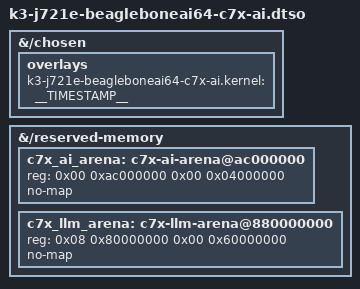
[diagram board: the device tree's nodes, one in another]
// SPDX-License-Identifier: MIT
// BeagleBone AI-64 C7x AI runtime overlay: reserves contiguous DDR tensor
// arenas (no-map) shared between Linux A72 and C7x DSP:
//   - 0xac000000  (64 MiB)  : primary / microbenchmark arena
//   - 0x880000000 (1.5 GiB) : large LLM model + KV cache + prefill arena (high DDR bank)

/dts-v1/;
/plugin/;

&{/chosen} {
	overlays {
		k3-j721e-beagleboneai64-c7x-ai.kernel = __TIMESTAMP__;
	};
};

&{/reserved-memory} {
	#address-cells = <2>;
	#size-cells = <2>;

	c7x_ai_arena: c7x-ai-arena@ac000000 {
		reg = <0x00 0xac000000 0x00 0x04000000>;
		no-map;
	};

	c7x_llm_arena: c7x-llm-arena@880000000 {
		reg = <0x08 0x80000000 0x00 0x60000000>;
		no-map;
	};
};
